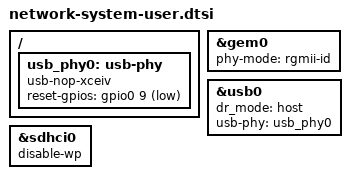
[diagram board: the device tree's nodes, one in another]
/include/ "system-conf.dtsi"

/ {
    usb_phy0: usb-phy {
        compatible = "usb-nop-xceiv";
        #phy-cells = <0>;
        reset-gpios = <&gpio0 9 1>;
    };
};

&gem0 {
    status = "okay";
    phy-mode = "rgmii-id";
};

&usb0 {
    status = "okay";
    dr_mode = "host";
    usb-phy = <&usb_phy0>;
};

&sdhci0 {
    status = "okay";
    disable-wp;
};
